# GD32E50x_CL register map
File version: 1.0
CPU: CM33 r0p0, little endian, MPU, FPU, 4 interrupt priority bits
Registers are 32-bit, read-write, reset 0x0 unless marked. A register's access mark holds for its fields unless they carry their own. Offsets are from the block's base; [hi:lo] are bit positions.

## TIMER5 — Basic-timers
Base 0x40001000
Same registers: TIMER6 0x40001400
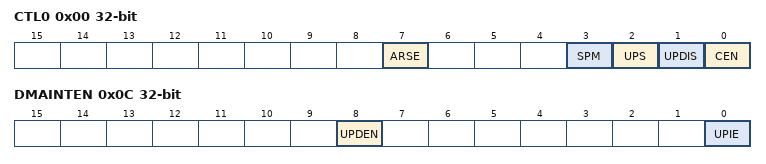
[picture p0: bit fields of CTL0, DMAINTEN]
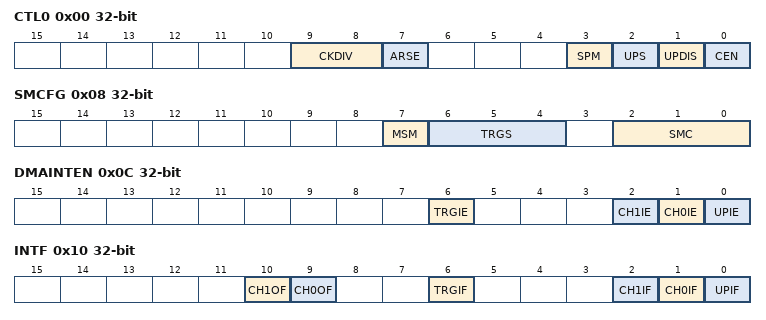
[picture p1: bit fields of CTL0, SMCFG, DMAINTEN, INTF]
0x00 CTL0 — control register 0
  [7] ARSE — Auto-reload shadow enable
  [3] SPM — Single pulse mode
  [2] UPS — Update source
  [1] UPDIS — Update disable
  [0] CEN — Counter enable
0x04 CTL1 — control register 1
  [6:4] MMC — Master mode control
0x0C DMAINTEN — DMA/Interrupt enable register
  [8] UPDEN — Update DMA request enable
  [0] UPIE — Update interrupt enable
0x10 INTF — Interrupt flag register
  [0] UPIF — Update interrupt flag
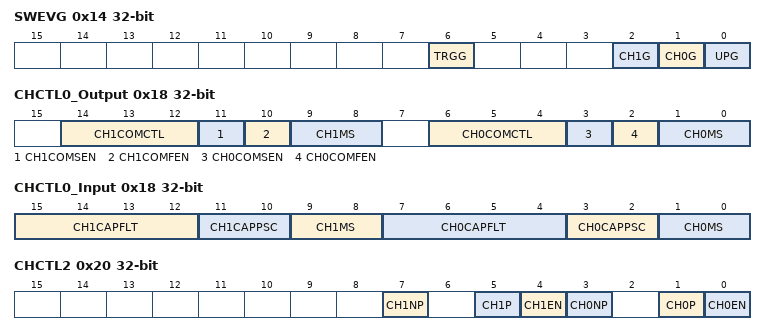
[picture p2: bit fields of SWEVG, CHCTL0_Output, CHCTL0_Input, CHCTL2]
0x14 SWEVG wo — event generation register
  [0] UPG — Update generation
0x24 CNT — Counter register
  [15:0] CNT — Low counter value
0x28 PSC — Prescaler register
  [15:0] PSC — Prescaler value of the counter clock
0x2C CAR — Counter auto reload register
  [15:0] CARL — Counter auto reload value

## TIMER8 — General-purpose-timers
Base 0x40014C00
Same registers: TIMER11 0x40001800
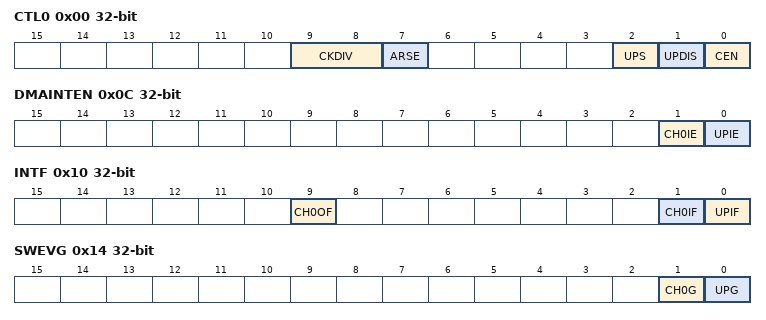
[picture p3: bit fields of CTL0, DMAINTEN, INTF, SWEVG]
0x00 CTL0 — control register 0
  [9:8] CKDIV — Clock division
  [7] ARSE — Auto-reload shadow enable
  [3] SPM — Single pulse mode
  [2] UPS — Update source
  [1] UPDIS — Update disable
  [0] CEN — Counter enable
0x08 SMCFG — slave mode configuration register
  [7] MSM — Master-slave mode
  [6:4] TRGS — Trigger selection
  [2:0] SMC — Slave mode control
0x0C DMAINTEN — DMA and interrupt enable register
  [6] TRGIE — Trigger interrupt enable
  [2] CH1IE — Channel 1 capture/compare interrupt enable
  [1] CH0IE — Channel 0 capture/compare interrupt enable
  [0] UPIE — Update interrupt enable
0x10 INTF — interrupt flag register
  [10] CH1OF — Channel 1 over capture flag
  [9] CH0OF — Channel 0 over capture flag
  [6] TRGIF — Trigger interrupt flag
  [2] CH1IF — Channel 1 capture/compare interrupt flag
  [1] CH0IF — Channel 0 capture/compare interrupt flag
  [0] UPIF — Update interrupt flag
0x14 SWEVG wo — event generation register
  [6] TRGG — Trigger event generation
  [2] CH1G — Channel 1 capture or compare event generation
  [1] CH0G — Channel 0 capture or compare event generation
  [0] UPG — Update generation
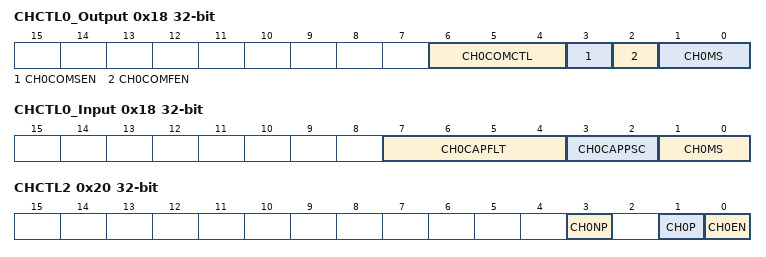
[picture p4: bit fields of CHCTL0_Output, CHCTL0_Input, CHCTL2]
0x18 CHCTL0_Output — Channel control register 0 (output mode)
  [14:12] CH1COMCTL — Channel 1 compare output control
  [11] CH1COMSEN — Channel 1 output compare shadow enable
  [10] CH1COMFEN — Channel 1 output compare fast enable
  [9:8] CH1MS — Channel 1 mode selection
  [6:4] CH0COMCTL — Channel 0 compare output control
  [3] CH0COMSEN — Channel 0 compare output shadow enable
  [2] CH0COMFEN — Channel 0 output compare fast enable
  [1:0] CH0MS — Channel 0 I/O mode selection
0x18 CHCTL0_Input (alternate view of CHCTL0_Output) — Channel control register 0 (input mode)
  [15:12] CH1CAPFLT — Channel 1 input capture filter control
  [11:10] CH1CAPPSC — Channel 1 input capture prescaler
  [9:8] CH1MS — Channel 1 mode selection
  [7:4] CH0CAPFLT — Channel 0 input capture filter control
  [3:2] CH0CAPPSC — Channel 0 input capture prescaler
  [1:0] CH0MS — Channel 0 mode selection
0x20 CHCTL2 — Channel control register 2
  [7] CH1NP — Channel 1 complementary output polarity
  [5] CH1P — Channel 1 capture/compare function polarity
  [4] CH1EN — Channel 1 capture/compare function enable
  [3] CH0NP — Channel 0 complementary output polarity
  [1] CH0P — Channel 0 capture/compare function polarity
  [0] CH0EN — Channel 0 capture/compare function enable
0x24 CNT — Counter register
  [15:0] CNT — current counter value
0x28 PSC — Prescaler register
  [15:0] PSC — Prescaler value of the counter clock
0x2C CAR — Counter auto reload register
  [15:0] CARL — Counter auto reload value
0x34 CH0CV — Channel 0 capture/compare value register
  [15:0] CH0VAL — Capture or compare value of channel0
0x38 CH1CV — Channel 1 capture/compare value register
  [15:0] CH1VAL — Capture or compare value of channel1
0xFC CFG — configuration register
  [1] CHVSEL — Write CHxVAL register selection

## TIMER9 — General-purpose-timers
Base 0x40015000
Same registers: TIMER12 0x40001C00, TIMER13 0x40002000, TIMER10 0x40015400
0x00 CTL0 — control register 0
  [9:8] CKDIV — Clock division
  [7] ARSE — Auto-reload shadow enable
  [2] UPS — Update source
  [1] UPDIS — Update disable
  [0] CEN — Counter enable
0x04 CTL1 — control register 1
  [6:4] MMC — Master mode control
0x0C DMAINTEN — DMA/Interrupt enable register
  [1] CH0IE — Channel 0 capture/compare interrupt enable
  [0] UPIE — Update interrupt enable
0x10 INTF — interrupt flag register
  [9] CH0OF — Channel 0 over capture flag
  [1] CH0IF — Channel 0 capture/compare interrupt flag
  [0] UPIF — Update interrupt flag
0x14 SWEVG wo — event generation register
  [1] CH0G — Channel 0 capture or compare event generation
  [0] UPG — Update generation
0x18 CHCTL0_Output — Channel control register 0 (output mode)
  [6:4] CH0COMCTL — Channel 0 compare output control
  [3] CH0COMSEN — Channel 0 compare output shadow enable
  [2] CH0COMFEN — Channel 0 output compare fast enable
  [1:0] CH0MS — Channel 0 I/O mode selection
0x18 CHCTL0_Input (alternate view of CHCTL0_Output) — Channel control register 0 ( (input mode)
  [7:4] CH0CAPFLT — Channel 0 input capture filter control
  [3:2] CH0CAPPSC — Channel 0 input capture prescaler
  [1:0] CH0MS — Channel 0 mode selection
0x20 CHCTL2 — Channel control register 2
  [3] CH0NP — Channel 0 complementary output polarity
  [1] CH0P — Channel 0 capture/compare polarity
  [0] CH0EN — Channel 0 capture/compare function enable
0x24 CNT — Counter register
  [15:0] CNT — current counter value
0x28 PSC — Prescaler register
  [15:0] PSC — Prescaler value of the counter clock
0x2C CAR — Counter auto reload register
  [15:0] CARL — Counter auto reload value
0x34 CH0CV — Channel 0 capture/compare value register
  [15:0] CH0VAL — Capture or compare value of channel 0
0xFC CFG — configuration register
  [1] CHVSEL — Write CHxVAL register selection

## TMU
Base 0x40080000
0x00 IDATA0 reset 0x3F800000 — Input data0 register
0x04 IDATA1 reset 0x3F800000 — Input data1 register
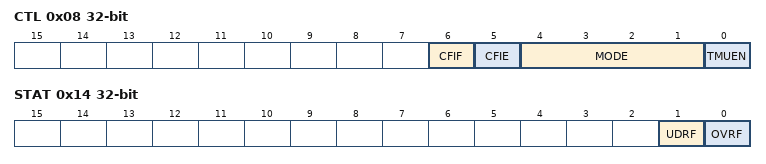
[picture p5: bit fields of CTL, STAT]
0x08 CTL access per field — Control register
  [6] CFIF ro
  [5] CFIE rw
  [4:1] MODE rw — Set the mode of TMU
  [0] TMUEN rw — start TMU module calculation
0x0C DATA0 reset 0x34000000
0x10 DATA1
0x14 STAT ro — Status register
  [1] UDRF — The flag of underflow
  [0] OVRF — The flag of overflow

## USBHS_PWRCLK — USB on the go high speed
Base 0x50000E00
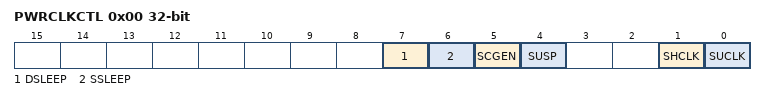
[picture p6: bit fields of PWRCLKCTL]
0x00 PWRCLKCTL access per field — power and clock gating control register (PWRCLKCTL)
  [7] DSLEEP ro — PHY is in deep sleep status
  [6] SSLEEP ro — PHY is in shallow sleep status
  [5] SCGEN ro — internal clock gating enable
  [4] SUSP ro — PHY is in suspend status
  [1] SHCLK rw — Stop HCLK
  [0] SUCLK rw — Stop the USB clock

## WWDGT — Window watchdog timer
Base 0x40002C00
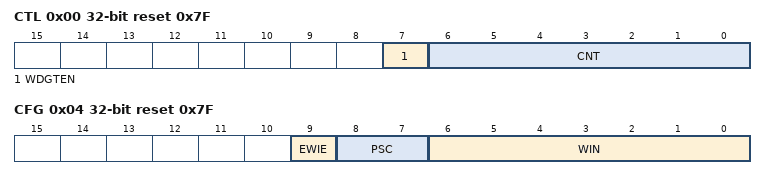
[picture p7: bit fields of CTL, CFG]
0x00 CTL reset 0x7F — Control register
  [7] WDGTEN — Activation bit
  [6:0] CNT — 7-bit counter
0x04 CFG reset 0x7F — Configuration register
  [9] EWIE — Early wakeup interrupt
  [8:7] PSC — Prescaler
  [6:0] WIN — 7-bit window value
0x08 STAT — Status register
  [0] EWIF — Early wakeup interrupt flag
